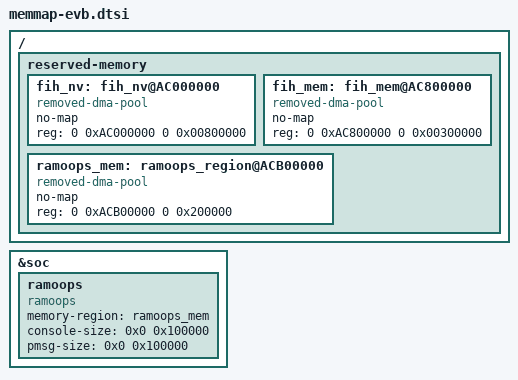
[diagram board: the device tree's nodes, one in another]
/* ref: sdm660.dtsi */

/ {
	reserved-memory {
		fih_nv: fih_nv@AC000000 {
			compatible = "removed-dma-pool";
			no-map;
			reg = <0 0xAC000000 0 0x00800000>;
		};
		fih_mem: fih_mem@AC800000 {
			compatible = "removed-dma-pool";
			no-map;
			reg = <0 0xAC800000 0 0x00300000>;
		};
//		pstore_region: pstore_region@ACB00000 {
//			compatible = "removed-dma-pool";
//			no-map;
//			reg = <0 0xACB00000 0 0x00200000>;
//		};

	        ramoops_mem: ramoops_region@ACB00000 {
			compatible = "removed-dma-pool";
			no-map;
			reg = <0 0xACB00000 0 0x200000>;
		};
	};
};



&soc {
	ramoops {
		compatible = "ramoops";
		memory-region = <&ramoops_mem>;
		console-size = <0x0 0x100000>;
		pmsg-size = <0x0 0x100000>;
	};
};
